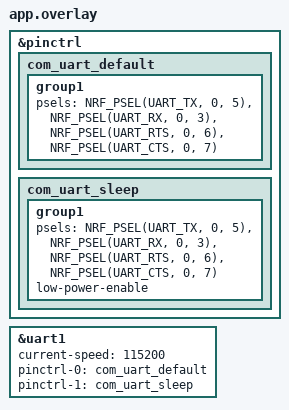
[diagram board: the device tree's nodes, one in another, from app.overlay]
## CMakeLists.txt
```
#
# Copyright (c) 2020 Nordic Semiconductor ASA
#
# SPDX-License-Identifier: LicenseRef-Nordic-5-Clause
#
cmake_minimum_required(VERSION 3.20.0)

find_package(Zephyr REQUIRED HINTS $ENV{ZEPHYR_BASE})
project(sensor_client)

# NORDIC SDK APP START
target_sources(app PRIVATE
	src/main.c
	src/comm.c
	src/model_handler.c)
target_include_directories(app PRIVATE include)
# NORDIC SDK APP END
```

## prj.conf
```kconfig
#
# Copyright (c) 2020 Nordic Semiconductor ASA
#
# SPDX-License-Identifier: LicenseRef-Nordic-5-Clause
#
CONFIG_NCS_SAMPLES_DEFAULTS=y

# Deferred logging helps improve LPN power consumption
# when friendship is established.
CONFIG_LOG_MODE_DEFERRED=y

# General configuration
CONFIG_NCS_APPLICATION_BOOT_BANNER_STRING="Mesh Sensor Observer"
CONFIG_SYSTEM_WORKQUEUE_STACK_SIZE=2048
CONFIG_FLASH=y
CONFIG_FLASH_MAP=y
# Flash shell module uses 8k of RAM for testing buffers, disable to save RAM
CONFIG_FLASH_SHELL=n
CONFIG_NVS=y
CONFIG_NVS_LOOKUP_CACHE=y
CONFIG_SETTINGS=y
CONFIG_SETTINGS_NVS_NAME_CACHE=y
CONFIG_HWINFO=y
CONFIG_DK_LIBRARY=y
CONFIG_PM_SINGLE_IMAGE=y
CONFIG_PM_PARTITION_SIZE_SETTINGS_STORAGE=0x8000
CONFIG_SOC_FLASH_NRF_PARTIAL_ERASE=y
CONFIG_CBPRINTF_FP_SUPPORT=y

# Bluetooth configuration
CONFIG_BT=y
CONFIG_BT_DEVICE_NAME="Mesh Sensor Observer"
CONFIG_BT_L2CAP_TX_BUF_COUNT=8
CONFIG_BT_OBSERVER=y
CONFIG_BT_PERIPHERAL=y
CONFIG_BT_SETTINGS=y

# Disable unused Bluetooth features
CONFIG_BT_CTLR_LE_ENC=n
CONFIG_BT_PHY_UPDATE=n
CONFIG_BT_CTLR_CHAN_SEL_2=n
CONFIG_BT_CTLR_MIN_USED_CHAN=n
CONFIG_BT_CTLR_PRIVACY=n

# Bluetooth Mesh configuration
CONFIG_BT_MESH=y
CONFIG_BT_MESH_RELAY=y
CONFIG_BT_MESH_FRIEND=y
CONFIG_BT_MESH_TX_SEG_MAX=24
CONFIG_BT_MESH_RX_SEG_MAX=16
CONFIG_BT_MESH_PB_GATT=y
CONFIG_BT_MESH_GATT_PROXY=y
CONFIG_BT_MESH_PROXY_USE_DEVICE_NAME=y
CONFIG_BT_MESH_DK_PROV=y
CONFIG_BT_MESH_SUBNET_COUNT=2
CONFIG_BT_MESH_APP_KEY_COUNT=3
CONFIG_BT_MESH_MODEL_KEY_COUNT=3
CONFIG_BT_MESH_CRPL=32
CONFIG_BT_MESH_MSG_CACHE_SIZE=64
CONFIG_BT_MESH_SHELL=y

# Bluetooth Mesh models
CONFIG_BT_MESH_SENSOR_CLI=y

# # LOGGING
CONFIG_LOG=y
CONFIG_USE_SEGGER_RTT=y
CONFIG_LOG_BACKEND_RTT=y
CONFIG_LOG_BACKEND_UART=n
CONFIG_RTT_CONSOLE=y
CONFIG_UART_CONSOLE=n

# Uart 
CONFIG_SERIAL=y

# cJSON
CONFIG_CJSON_LIB=y
CONFIG_NEWLIB_LIBC=y
CONFIG_NEWLIB_LIBC_FLOAT_PRINTF=y
```

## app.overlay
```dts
&pinctrl {
	com_uart_default: com_uart_default {
		group1 {
			psels = <NRF_PSEL(UART_TX, 0, 5)>, // TX as per the nrf52840 Host Board schematic
				<NRF_PSEL(UART_RX, 0, 3)>, // RX as per the nrf52840 Host Board schematic
				<NRF_PSEL(UART_RTS, 0, 6)>,
				<NRF_PSEL(UART_CTS, 0, 7)>;
		};
	};

	com_uart_sleep: com_uart_sleep {
		group1 {
			psels = <NRF_PSEL(UART_TX, 0, 5)>, // TX as per the nrf52840 Host Board schematic
				<NRF_PSEL(UART_RX, 0, 3)>, // RX as per the nrf52840 Host Board schematic
				<NRF_PSEL(UART_RTS, 0, 6)>,
				<NRF_PSEL(UART_CTS, 0, 7)>;
			low-power-enable;
		};
	};

};


&uart1 {
    status = "okay";
    current-speed = <115200>;
    pinctrl-0 = <&com_uart_default>;
    pinctrl-1 = <&com_uart_sleep>;
    pinctrl-names = "default", "sleep";
};
```

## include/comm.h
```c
#pragma once 

int comm_init(void);
void comm_print(char *buf);
```

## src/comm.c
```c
#include <zephyr/kernel.h>
#include <zephyr/device.h>
#include <zephyr/drivers/uart.h>

#include <string.h>
#include "comm.h"

// #define UART_DEVICE_NODE DT_CHOSEN(zephyr_shell_uart)
static const struct device *const uart_dev = DEVICE_DT_GET(DT_NODELABEL(uart1));

void comm_print(char *buf)
{
	int msg_len = strlen(buf);

	for (int i = 0; i < msg_len; i++) {
		uart_poll_out(uart_dev, buf[i]);
	}
    uart_poll_out(uart_dev, '\r');
    uart_poll_out(uart_dev, '\n');
}

int comm_init(void)
{
	if (!device_is_ready(uart_dev)) {
		printk("UART device not found!");
        return -1;
	}

    return 0;
}
```

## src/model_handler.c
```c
/*
 * Copyright (c) 2020 Nordic Semiconductor ASA
 *
 * SPDX-License-Identifier: LicenseRef-Nordic-5-Clause
 */

#include <zephyr/bluetooth/bluetooth.h>
#include <bluetooth/mesh/models.h>
#include <dk_buttons_and_leds.h>
#include <cJSON.h>
#include <stdio.h>
#include "model_handler.h"
#include "comm.h"
#include <zephyr/logging/log.h>

LOG_MODULE_REGISTER(sensor_logger, LOG_LEVEL_INF);

#define GET_DATA_INTERVAL 60000
#define GET_DATA_INTERVAL_QUICK 3000
#define MOTION_TIMEOUT K_SECONDS(60)
#define COMBINE_INTERVAL K_MSEC(500)

static bool is_occupied;
static struct k_work_delayable motion_timeout_work;
static struct k_work_delayable send_data_work;

static cJSON *sensor_data = NULL;

static void send_json_over_uart(void)
{
    if (sensor_data && cJSON_GetArraySize(sensor_data) > 0) 
    {
        char *json_str = cJSON_PrintUnformatted(sensor_data);
        if (json_str) 
        {
            comm_print(json_str);
            cJSON_free(json_str);
        }
        cJSON_Delete(sensor_data);
        sensor_data = cJSON_CreateObject();
    }
}

static void add_sensor_value_to_json(const char *key, const struct bt_mesh_sensor_value *value)
{
    if (value && key) {
        char value_str[32];
        snprintf(value_str, sizeof(value_str), "%s", bt_mesh_sensor_ch_str(value));
        cJSON_AddStringToObject(sensor_data, key, value_str);
    }
}

static void motion_timeout(struct k_work *work)
{
	is_occupied = false;
	printk("Area is now vacant.\n");
}

static void sensor_cli_data_cb(struct bt_mesh_sensor_cli *cli,
			       struct bt_mesh_msg_ctx *ctx,
			       const struct bt_mesh_sensor_type *sensor,
			       const struct bt_mesh_sensor_value *value)
{
	enum bt_mesh_sensor_value_status status;
    if (!sensor_data) {
        sensor_data = cJSON_CreateObject();
    }

	if (sensor->id == bt_mesh_sensor_present_dev_op_temp.id) {
		printk("Chip temperature: %s\n", bt_mesh_sensor_ch_str(value));
	} else if (sensor->id == bt_mesh_sensor_presence_detected.id) {
		int64_t presence_detected = 0;

		status = bt_mesh_sensor_value_to_micro(value, &presence_detected);
		if (!bt_mesh_sensor_value_status_is_numeric(status)) {
			printk("Warning: unexpected behaviour during conversion of presence "
			       "detected value (%d)\n",
			       status);
			return;
		}
		if (!!presence_detected) {
			printk("Presence detected\n");
		} else {
			printk("No presence detected\n");
		}
	} else if (sensor->id ==
		   bt_mesh_sensor_time_since_presence_detected.id) {
		int64_t time_since_presence_detected = 0;

		status = bt_mesh_sensor_value_to_micro(value, &time_since_presence_detected);
		if (status == BT_MESH_SENSOR_VALUE_UNKNOWN) {
			printk("Unknown last presence detected\n");
		} else if (!time_since_presence_detected) {
			printk("Presence detected, or under 1 second since presence detected\n");
		} else {
			printk("%s second(s) since last presence detected\n",
			       bt_mesh_sensor_ch_str(value));
		}
	} else if (sensor->id == bt_mesh_sensor_present_amb_light_level.id) {
		printk("Ambient light level: %s\n", bt_mesh_sensor_ch_str(value));
	} else if (sensor->id == bt_mesh_sensor_motion_sensed.id) {
		int64_t motion_sensed = 0;

		status = bt_mesh_sensor_value_to_micro(value, &motion_sensed);
		if (!bt_mesh_sensor_value_status_is_numeric(status)) {
			printk("Warning: unexpected behaviour during conversion of motion sensed "
			       "value (%d)\n",
			       status);
			return;
		}
		if (!!motion_sensed) {
			is_occupied = true;
			printk("Motion detected (%s %%). Area is occupied.\n",
			       bt_mesh_sensor_ch_str(value));
			k_work_cancel_delayable(&motion_timeout_work);
		} else {
			if (is_occupied) {
				printk("No current motion detected. Area is still occupied.\n");
				k_work_reschedule(&motion_timeout_work, MOTION_TIMEOUT);
			} else {
				printk("No motion detected. Area is vacant.\n");
			}
		}
	} else if (sensor->id == bt_mesh_sensor_time_since_motion_sensed.id) {
		int64_t time_since_motion_sensed = 0;

		status = bt_mesh_sensor_value_to_micro(value, &time_since_motion_sensed);
		if (status == BT_MESH_SENSOR_VALUE_UNKNOWN) {
			printk("Unknown last motion sensed\n");
		} else if (!time_since_motion_sensed) {
			printk("Motion sensed, or under 1 second since motion sensed\n");
		} else {
			printk("%s second(s) since last motion sensed\n",
			       bt_mesh_sensor_ch_str(value));
		}
	} else if (sensor->id == bt_mesh_sensor_people_count.id) {
		printk("People count is %s\n", bt_mesh_sensor_ch_str(value));
	}
    else if (sensor->id == bt_mesh_sensor_precise_present_amb_temp.id) {
        // LOG_INF("Ambient Temperature is %s\n", bt_mesh_sensor_ch_str(value));
        add_sensor_value_to_json("temperature", value);
	}
    else if (sensor->id == bt_mesh_sensor_present_amb_rel_humidity.id) {
        // LOG_INF("Ambient Humidity is %s\n", bt_mesh_sensor_ch_str(value));
        add_sensor_value_to_json("humidity", value);
	}
    else if (sensor->id == bt_mesh_sensor_present_input_voltage.id) {
        // LOG_INF("Voltage is %sV\n", bt_mesh_sensor_ch_str(value));
        add_sensor_value_to_json("voltage", value);
	}

    if (k_work_delayable_is_pending(&send_data_work)) {
        k_work_cancel_delayable(&send_data_work);
    }
    k_work_reschedule(&send_data_work, COMBINE_INTERVAL);
}

static void sensor_cli_series_entry_cb(
	struct bt_mesh_sensor_cli *cli, struct bt_mesh_msg_ctx *ctx,
	const struct bt_mesh_sensor_type *sensor, uint8_t index, uint8_t count,
	const struct bt_mesh_sensor_series_entry *entry)
{
	printk("Relative runtime in %s", bt_mesh_sensor_ch_str(&entry->value[1]));
	printk(" to %s degrees: ", bt_mesh_sensor_ch_str(&entry->value[2]));
	printk("%s percent\n", bt_mesh_sensor_ch_str(&entry->value[0]));
}

static void sensor_cli_setting_status_cb(struct bt_mesh_sensor_cli *cli,
					 struct bt_mesh_msg_ctx *ctx,
					 const struct bt_mesh_sensor_type *sensor,
					 const struct bt_mesh_sensor_setting_status *setting)
{
	printk("Sensor ID: 0x%04x, Setting ID: 0x%04x\n", sensor->id, setting->type->id);
	for (int chan = 0; chan < setting->type->channel_count; chan++) {
		printk("\tChannel %d value: %s\n", chan,
		       bt_mesh_sensor_ch_str(&(setting->value[chan])));
	}
}

static void sensor_cli_desc_cb(struct bt_mesh_sensor_cli *cli, struct bt_mesh_msg_ctx *ctx,
			       const struct bt_mesh_sensor_info *sensor)
{
	printk("Descriptor of sensor with ID 0x%04x:\n", sensor->id);
	printk("\ttolerance: { positive: %d negative: %d }\n",
	       sensor->descriptor.tolerance.positive, sensor->descriptor.tolerance.negative);
	printk("\tsampling type: %d\n", sensor->descriptor.sampling_type);
}

static const struct bt_mesh_sensor_cli_handlers bt_mesh_sensor_cli_handlers = {
	.data = sensor_cli_data_cb,
	.series_entry = sensor_cli_series_entry_cb,
	.setting_status = sensor_cli_setting_status_cb,
	.sensor = sensor_cli_desc_cb,
};

static struct bt_mesh_sensor_cli sensor_cli =
	BT_MESH_SENSOR_CLI_INIT(&bt_mesh_sensor_cli_handlers);

static struct k_work_delayable get_data_work;

static void get_data(struct k_work *work)
{
	if (!bt_mesh_is_provisioned()) {
		k_work_schedule(&get_data_work, K_MSEC(GET_DATA_INTERVAL));
		return;
	}

	static uint32_t sensor_idx;
	int err;

	/* Only one message can be published at a time. Swap sensor after each timeout. */
	switch (sensor_idx++) {
	case (0): {
		err = bt_mesh_sensor_cli_get(
			&sensor_cli, NULL, &bt_mesh_sensor_present_dev_op_temp,
			NULL);
		if (err) {
			printk("Error getting chip temperature (%d)\n", err);
		}
		break;
	}
	case (1): {
		err = bt_mesh_sensor_cli_series_entries_get(
			&sensor_cli, NULL,
			&bt_mesh_sensor_rel_runtime_in_a_dev_op_temp_range, NULL, NULL,
			NULL, NULL);
		if (err) {
			printk("Error getting relative chip temperature data (%d)\n", err);
		}
		break;
	}
	case (2): {
		err = bt_mesh_sensor_cli_get(
			&sensor_cli, NULL, &bt_mesh_sensor_time_since_presence_detected,
			NULL);
		if (err) {
			printk("Error getting time since presence detected (%d)\n", err);
		}
		break;
	}
	case (3): {
		err = bt_mesh_sensor_cli_get(
			&sensor_cli, NULL, &bt_mesh_sensor_present_amb_light_level, NULL);
		if (err) {
			printk("Error getting ambient light level (%d)\n", err);
		}
		break;
	}
	case (4): {
		err = bt_mesh_sensor_cli_get(&sensor_cli, NULL,
					     &bt_mesh_sensor_time_since_motion_sensed, NULL);
		if (err) {
			printk("Error getting time since motion detected (%d)\n", err);
		}
		break;
	}
	case (5): {
		err = bt_mesh_sensor_cli_get(&sensor_cli, NULL, &bt_mesh_sensor_people_count, NULL);
		if (err) {
			printk("Error getting people count (%d)\n", err);
		}
		break;
	}
	}

	if (sensor_idx % 6) {
		k_work_schedule(&get_data_work, K_MSEC(GET_DATA_INTERVAL_QUICK));
	} else {
		k_work_schedule(&get_data_work, K_MSEC(GET_DATA_INTERVAL));
		sensor_idx = 0;
	}
}

static const int temp_ranges[][2] = {
	{ 0, 100 },
	{ 10, 20 },
	{ 22, 30 },
	{ 40, 50 },
};

static const int presence_motion_threshold[] = { 0, 25, 50, 75, 100 };

static int setting_set_int(const struct bt_mesh_sensor_type *sensor_type,
			   const struct bt_mesh_sensor_type *setting_type,
			   const int *values)
{
	struct bt_mesh_sensor_value sensor_vals[CONFIG_BT_MESH_SENSOR_CHANNELS_MAX];
	int err;

	for (int i = 0; i < setting_type->channel_count; i++) {
		err = bt_mesh_sensor_value_from_micro(setting_type->channels[i].format,
						      values[i] * 1000000LL, &sensor_vals[i]);
		if (err) {
			return err;
		}
	}

	return bt_mesh_sensor_cli_setting_set(&sensor_cli, NULL, sensor_type,
					      setting_type, sensor_vals, NULL);
}

static void button_handler_cb(uint32_t pressed, uint32_t changed)
{
	if (!bt_mesh_is_provisioned()) {
		return;
	}

	static uint32_t temp_idx;
	static uint32_t motion_threshold_idx;
	int err;

	if (pressed & changed & BIT(0)) {
		err = bt_mesh_sensor_cli_setting_get(&sensor_cli, NULL,
						     &bt_mesh_sensor_present_dev_op_temp,
						     &bt_mesh_sensor_dev_op_temp_range_spec, NULL);
		if (err) {
			printk("Error getting range setting (%d)\n", err);
		}
	}
	if (pressed & changed & BIT(1)) {
		err = setting_set_int(&bt_mesh_sensor_present_dev_op_temp,
				      &bt_mesh_sensor_dev_op_temp_range_spec,
				      temp_ranges[temp_idx++]);
		if (err) {
			printk("Error setting range setting (%d)\n", err);
		}
		temp_idx = temp_idx % ARRAY_SIZE(temp_ranges);
	}
	if (pressed & changed & BIT(2)) {
		err = bt_mesh_sensor_cli_desc_get(&sensor_cli, NULL,
						  &bt_mesh_sensor_present_dev_op_temp, NULL);
		if (err) {
			printk("Error getting sensor descriptor (%d)\n", err);
		}
	}
	if (pressed & changed & BIT(3)) {
		err = setting_set_int(&bt_mesh_sensor_presence_detected,
				      &bt_mesh_sensor_motion_threshold,
				      &presence_motion_threshold[motion_threshold_idx++]);
		if (err) {
			printk("Error setting motion threshold setting (%d)\n", err);
		}
		motion_threshold_idx = motion_threshold_idx % ARRAY_SIZE(presence_motion_threshold);
	}
}

static struct button_handler button_handler = {
	.cb = button_handler_cb,
};

/* Set up a repeating delayed work to blink the DK's LEDs when attention is
 * requested.
 */
static struct k_work_delayable attention_blink_work;
static bool attention;

static void attention_blink(struct k_work *work)
{
	static int idx;
	const uint8_t pattern[] = {
		BIT(0) | BIT(1),
		BIT(1) | BIT(2),
		BIT(2) | BIT(3),
		BIT(3) | BIT(0),
	};

	if (attention) {
		dk_set_leds(pattern[idx++ % ARRAY_SIZE(pattern)]);
		k_work_reschedule(&attention_blink_work, K_MSEC(30));
	} else {
		dk_set_leds(DK_NO_LEDS_MSK);
	}
}

static void attention_on(const struct bt_mesh_model *mod)
{
	attention = true;
	k_work_reschedule(&attention_blink_work, K_NO_WAIT);
}

static void attention_off(const struct bt_mesh_model *mod)
{
	/* Will stop rescheduling blink timer */
	attention = false;
}

static const struct bt_mesh_health_srv_cb health_srv_cb = {
	.attn_on = attention_on,
	.attn_off = attention_off,
};

static struct bt_mesh_health_srv health_srv = {
	.cb = &health_srv_cb,
};

BT_MESH_HEALTH_PUB_DEFINE(health_pub, 0);

static struct bt_mesh_elem elements[] = {
	BT_MESH_ELEM(1,
		     BT_MESH_MODEL_LIST(BT_MESH_MODEL_CFG_SRV,
					BT_MESH_MODEL_HEALTH_SRV(&health_srv,
								 &health_pub),
					BT_MESH_MODEL_SENSOR_CLI(&sensor_cli)),
		     BT_MESH_MODEL_NONE),
};

static const struct bt_mesh_comp comp = {
	.cid = CONFIG_BT_COMPANY_ID,
	.elem = elements,
	.elem_count = ARRAY_SIZE(elements),
};

static void send_data_task(struct k_work *work)
{
    send_json_over_uart();
}

const struct bt_mesh_comp *model_handler_init(void)
{
    printk("cJSON version %s\n", cJSON_Version());
    comm_init();
	k_work_init_delayable(&attention_blink_work, attention_blink);
	k_work_init_delayable(&get_data_work, get_data);
	k_work_init_delayable(&motion_timeout_work, motion_timeout);
    k_work_init_delayable(&send_data_work, send_data_task);

	dk_button_handler_add(&button_handler);
	k_work_schedule(&get_data_work, K_MSEC(GET_DATA_INTERVAL));

	return &comp;
}
```
